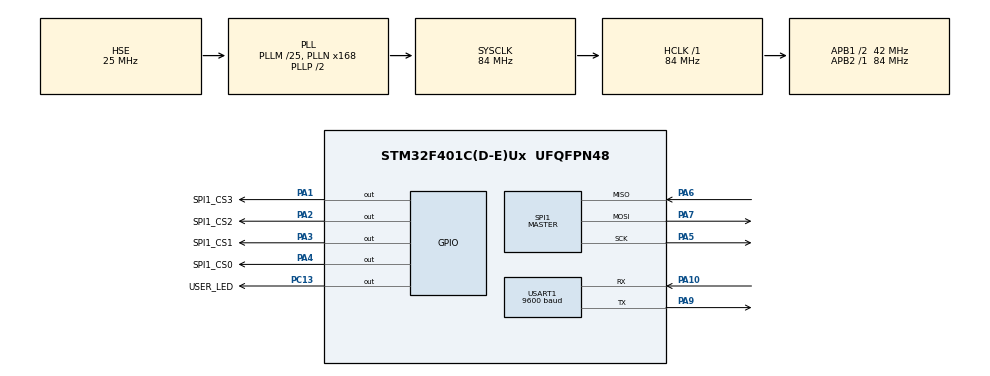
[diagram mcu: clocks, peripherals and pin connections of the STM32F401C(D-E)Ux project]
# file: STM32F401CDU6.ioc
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Mcu.Family=STM32F4
Mcu.Name=STM32F401C(D-E)Ux
Mcu.Package=UFQFPN48
NVIC.PriorityGroup=NVIC_PRIORITYGROUP_4
PA1.GPIO_Label=SPI1_CS3
PA1.GPIO_ModeDefaultOutputPP=GPIO_MODE_OUTPUT_PP
PA1.GPIO_PuPd=GPIO_NOPULL
PA1.GPIO_Speed=GPIO_SPEED_FREQ_VERY_HIGH
PA1.PinState=GPIO_PIN_SET
PA1.Signal=GPIO_Output
PA10.Mode=Asynchronous
PA10.Signal=USART1_RX
PA13.Mode=Trace_Asynchronous_SW
PA13.Signal=SYS_JTMS-SWDIO
PA14.Mode=Trace_Asynchronous_SW
PA14.Signal=SYS_JTCK-SWCLK
PA2.GPIO_Label=SPI1_CS2
PA2.GPIO_ModeDefaultOutputPP=GPIO_MODE_OUTPUT_PP
PA2.GPIO_PuPd=GPIO_NOPULL
PA2.GPIO_Speed=GPIO_SPEED_FREQ_VERY_HIGH
PA2.PinState=GPIO_PIN_SET
PA2.Signal=GPIO_Output
PA3.GPIO_Label=SPI1_CS1
PA3.GPIO_Speed=GPIO_SPEED_FREQ_VERY_HIGH
PA3.PinState=GPIO_PIN_SET
PA3.Signal=GPIO_Output
PA4.GPIO_Label=SPI1_CS0
PA4.GPIO_Speed=GPIO_SPEED_FREQ_VERY_HIGH
PA4.PinState=GPIO_PIN_SET
PA4.Signal=GPIO_Output
PA5.Mode=Full_Duplex_Master
PA5.Signal=SPI1_SCK
PA6.Mode=Full_Duplex_Master
PA6.Signal=SPI1_MISO
PA7.Mode=Full_Duplex_Master
PA7.Signal=SPI1_MOSI
PA9.Mode=Asynchronous
PA9.Signal=USART1_TX
PB3.Mode=Trace_Asynchronous_SW
PB3.Signal=SYS_JTDO-SWO
PC13-ANTI_TAMP.GPIO_Label=USER_LED
PC13-ANTI_TAMP.GPIO_ModeDefaultOutputPP=GPIO_MODE_OUTPUT_OD
PC13-ANTI_TAMP.GPIO_PuPd=GPIO_NOPULL
PC13-ANTI_TAMP.PinState=GPIO_PIN_SET
PC13-ANTI_TAMP.Signal=GPIO_Output
PH0\ -\ OSC_IN.Mode=HSE-External-Oscillator
PH0\ -\ OSC_IN.Signal=RCC_OSC_IN
PH1\ -\ OSC_OUT.Mode=HSE-External-Oscillator
PH1\ -\ OSC_OUT.Signal=RCC_OSC_OUT
ProjectManager.HeapSize=0x200
ProjectManager.StackSize=0x400
ProjectManager.TargetToolchain=EWARM V8.50
RCC.48MHZClocksFreq_Value=42000000
RCC.AHBFreq_Value=84000000
RCC.APB1CLKDivider=RCC_HCLK_DIV2
RCC.APB1Freq_Value=42000000
RCC.APB1TimFreq_Value=84000000
RCC.APB2Freq_Value=84000000
RCC.APB2TimFreq_Value=84000000
RCC.CortexFreq_Value=84000000
RCC.HCLKFreq_Value=84000000
RCC.HSE_VALUE=25000000
RCC.HSI_VALUE=16000000
RCC.LSE_VALUE=32768
RCC.PLLM=25
RCC.PLLN=168
RCC.PLLSourceVirtual=RCC_PLLSOURCE_HSE
RCC.SYSCLKFreq_VALUE=84000000
RCC.SYSCLKSource=RCC_SYSCLKSOURCE_PLLCLK
RCC.VCOOutputFreq_Value=168000000
SPI1.BaudRatePrescaler=SPI_BAUDRATEPRESCALER_256
SPI1.Direction=SPI_DIRECTION_2LINES
SPI1.Mode=SPI_MODE_MASTER
SPI1.VirtualType=VM_MASTER
USART1.BaudRate=9600
USART1.VirtualMode=VM_ASYNC
board=custom

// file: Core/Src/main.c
/* USER CODE BEGIN Header */
/**
 ******************************************************************************
 * @file           : main.c
 * @brief          : Main program body
 ******************************************************************************
 * @attention
 *
 * Copyright (c) 2024 STMicroelectronics.
 * All rights reserved.
 *
 * This software is licensed under terms that can be found in the LICENSE file
 * in the root directory of this software component.
 * If no LICENSE file comes with this software, it is provided AS-IS.
 *
 ******************************************************************************
 */
/* USER CODE END Header */
#include "main.h"
#include "gpio.h"
#include "spi.h"
#include "usart.h"

/* USER CODE BEGIN Includes */
#include "w25qxx_Demo.h"
/* USER CODE END Includes */

void SystemClock_Config(void);

int main(void)
{

    /* MCU Configuration--------------------------------------------------------*/

    /* Reset of all peripherals, Initializes the Flash interface and the Systick. */
    HAL_Init();

    /* Configure the system clock */
    SystemClock_Config();

    /* Initialize all configured peripherals */
    MX_GPIO_Init();
    MX_SPI1_Init();
    MX_USART1_UART_Init();
    /* USER CODE BEGIN 2 */
    HAL_GPIO_WritePin(USER_LED_GPIO_Port, USER_LED_Pin, GPIO_PIN_RESET);
    /* USER CODE END 2 */

    /* Infinite loop */
    /* USER CODE BEGIN WHILE */
    while (1)
    {
        if (w25qxx_Demo(w25qxx_Print))
            Error_Handler();
        HAL_GPIO_WritePin(USER_LED_GPIO_Port, USER_LED_Pin, GPIO_PIN_SET);
        /* USER CODE END WHILE */

    }
}

void SystemClock_Config(void)
{
    RCC_OscInitTypeDef RCC_OscInitStruct = {0};
    RCC_ClkInitTypeDef RCC_ClkInitStruct = {0};

    /** Configure the main internal regulator output voltage
     */
    __HAL_RCC_PWR_CLK_ENABLE();
    __HAL_PWR_VOLTAGESCALING_CONFIG(PWR_REGULATOR_VOLTAGE_SCALE2);

    /** Initializes the RCC Oscillators according to the specified parameters
     * in the RCC_OscInitTypeDef structure.
     */
    RCC_OscInitStruct.OscillatorType = RCC_OSCILLATORTYPE_HSE;
    RCC_OscInitStruct.HSEState = RCC_HSE_ON;
    RCC_OscInitStruct.PLL.PLLState = RCC_PLL_ON;
    RCC_OscInitStruct.PLL.PLLSource = RCC_PLLSOURCE_HSE;
    RCC_OscInitStruct.PLL.PLLM = 25;
    RCC_OscInitStruct.PLL.PLLN = 168;
    RCC_OscInitStruct.PLL.PLLP = RCC_PLLP_DIV2;
    RCC_OscInitStruct.PLL.PLLQ = 4;
    if (HAL_RCC_OscConfig(&RCC_OscInitStruct) != HAL_OK)
    {
        Error_Handler();
    }

    /** Initializes the CPU, AHB and APB buses clocks
     */
    RCC_ClkInitStruct.ClockType = RCC_CLOCKTYPE_HCLK | RCC_CLOCKTYPE_SYSCLK | RCC_CLOCKTYPE_PCLK1 | RCC_CLOCKTYPE_PCLK2;
    RCC_ClkInitStruct.SYSCLKSource = RCC_SYSCLKSOURCE_PLLCLK;
    RCC_ClkInitStruct.AHBCLKDivider = RCC_SYSCLK_DIV1;
    RCC_ClkInitStruct.APB1CLKDivider = RCC_HCLK_DIV2;
    RCC_ClkInitStruct.APB2CLKDivider = RCC_HCLK_DIV1;

    if (HAL_RCC_ClockConfig(&RCC_ClkInitStruct, FLASH_LATENCY_2) != HAL_OK)
    {
        Error_Handler();
    }
}

void Error_Handler(void)
{
    __disable_irq();
    while (1) {}
}
